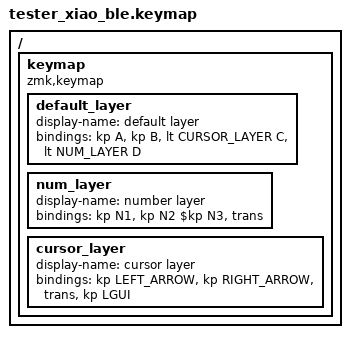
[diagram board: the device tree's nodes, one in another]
#include <behaviors.dtsi>
#include <dt-bindings/zmk/keys.h>
#include <dt-bindings/zmk/bt.h>
#include <dt-bindings/zmk/outputs.h>

#define NUM_LAYER 1
#define CURSOR_LAYER 2

/ {
    keymap {
        compatible = "zmk,keymap";
        default_layer {
            display-name = "default layer";
            bindings = <
                &kp A              &kp B
                &lt CURSOR_LAYER C &lt NUM_LAYER D
            >;
        };
        num_layer {
            display-name = "number layer";
            bindings = <
                &kp N1 &kp N2
                $kp N3 &trans
            >;
        };

        cursor_layer {
            display-name = "cursor layer";
            bindings = <
                &kp LEFT_ARROW &kp RIGHT_ARROW
                &trans         &kp LGUI
            >;
        };
    };

};

